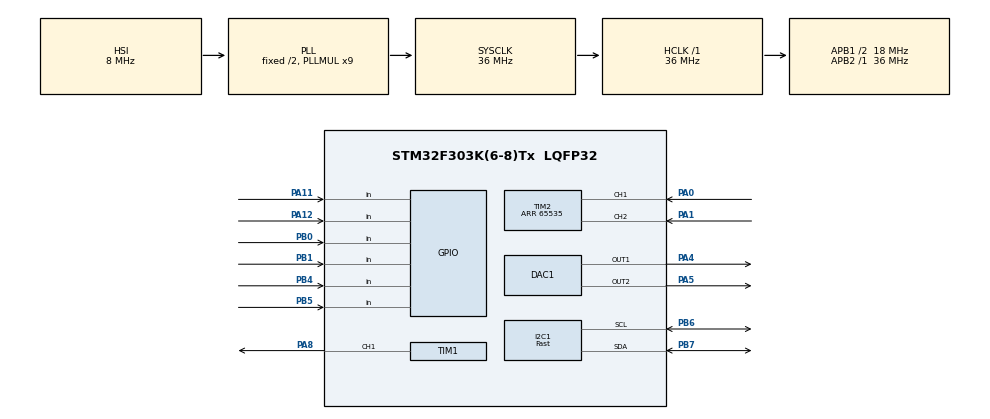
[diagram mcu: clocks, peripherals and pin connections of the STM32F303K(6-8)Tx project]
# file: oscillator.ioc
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DAC1.DAC_Trigger=DAC_TRIGGER_T6_TRGO
DAC1.DAC_Trigger2=DAC_TRIGGER_T6_TRGO
Dma.DAC1_CH1.0.Direction=DMA_MEMORY_TO_PERIPH
Dma.DAC1_CH1.0.Instance=DMA1_Channel3
Dma.DAC1_CH1.0.MemDataAlignment=DMA_MDATAALIGN_HALFWORD
Dma.DAC1_CH1.0.MemInc=DMA_MINC_ENABLE
Dma.DAC1_CH1.0.Mode=DMA_CIRCULAR
Dma.DAC1_CH1.0.PeriphDataAlignment=DMA_PDATAALIGN_HALFWORD
Dma.DAC1_CH1.0.PeriphInc=DMA_PINC_DISABLE
Dma.DAC1_CH1.0.Priority=DMA_PRIORITY_MEDIUM
Dma.Request0=DAC1_CH1
I2C1.I2C_Speed_Mode=I2C_Fast
I2C1.Timing=0x00301739
Mcu.Family=STM32F3
Mcu.Name=STM32F303K(6-8)Tx
Mcu.Package=LQFP32
NVIC.DMA1_Channel3_IRQn=true\:0\:0\:false\:false\:true\:false\:true\:true
NVIC.PriorityGroup=NVIC_PRIORITYGROUP_4
PA0.Signal=S_TIM2_CH1_ETR
PA1.Signal=S_TIM2_CH2
PA11.GPIO_PuPd=GPIO_PULLDOWN
PA11.Signal=GPIO_Input
PA12.GPIO_PuPd=GPIO_PULLDOWN
PA12.Signal=GPIO_Input
PA4.Signal=COMP_DAC11_group
PA5.Signal=COMP_DAC12_group
PA8.GPIO_Speed=GPIO_SPEED_FREQ_HIGH
PA8.Signal=S_TIM1_CH1
PB0.GPIO_PuPd=GPIO_PULLDOWN
PB0.Signal=GPIO_Input
PB1.GPIO_PuPd=GPIO_PULLDOWN
PB1.Signal=GPIO_Input
PB4.GPIO_PuPd=GPIO_PULLDOWN
PB4.Signal=GPIO_Input
PB5.GPIO_PuPd=GPIO_PULLDOWN
PB5.Signal=GPIO_Input
PB6.Mode=I2C
PB6.Signal=I2C1_SCL
PB7.Mode=I2C
PB7.Signal=I2C1_SDA
PF0\ /\ OSC_IN.Mode=HSE-External-Oscillator
PF0\ /\ OSC_IN.Signal=RCC_OSC_IN
PF1\ /\ OSC_OUT.Mode=HSE-External-Oscillator
PF1\ /\ OSC_OUT.Signal=RCC_OSC_OUT
ProjectManager.HeapSize=0x200
ProjectManager.StackSize=0x400
ProjectManager.TargetToolchain=STM32CubeIDE
RCC.AHBFreq_Value=36000000
RCC.APB1CLKDivider=RCC_HCLK_DIV2
RCC.APB1Freq_Value=18000000
RCC.APB1TimFreq_Value=36000000
RCC.APB2Freq_Value=36000000
RCC.APB2TimFreq_Value=36000000
RCC.CortexFreq_Value=36000000
RCC.HCLKFreq_Value=36000000
RCC.HSE_VALUE=8000000
RCC.HSI_VALUE=8000000
RCC.I2c1ClockSelection=RCC_I2C1CLKSOURCE_SYSCLK
RCC.PLLMUL=RCC_PLL_MUL9
RCC.SYSCLKFreq_VALUE=36000000
RCC.SYSCLKSourceVirtual=RCC_SYSCLKSOURCE_PLLCLK
SH.COMP_DAC11_group.0=DAC1_OUT1,DAC_OUT1
SH.COMP_DAC12_group.0=DAC1_OUT2,DAC_OUT2
SH.S_TIM1_CH1.0=TIM1_CH1,PWM Generation1 CH1
SH.S_TIM2_CH1_ETR.0=TIM2_CH1,Encoder_Interface
SH.S_TIM2_CH2.0=TIM2_CH2,Encoder_Interface
TIM1.AutoReloadPreload=TIM_AUTORELOAD_PRELOAD_ENABLE
TIM1.Channel-PWM\ Generation1\ CH1=TIM_CHANNEL_1
TIM2.EncoderMode=TIM_ENCODERMODE_TI12
TIM2.IC1Filter=5
TIM2.IC2Filter=5
TIM2.Period=65535
TIM6.TIM_MasterOutputTrigger=TIM_TRGO_UPDATE
VP_TIM1_VS_ClockSourceINT.Mode=Internal
VP_TIM6_VS_ClockSourceINT.Mode=Enable_Timer
board=custom

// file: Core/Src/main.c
/* USER CODE BEGIN Header */
/**
  ******************************************************************************
  * @file           : main.c
  * @brief          : Main program body
  ******************************************************************************
  * @attention
  *
  * Copyright (c) 2026 STMicroelectronics.
  * All rights reserved.
  *
  * This software is licensed under terms that can be found in the LICENSE file
  * in the root directory of this software component.
  * If no LICENSE file comes with this software, it is provided AS-IS.
  *
  ******************************************************************************
  */
/* USER CODE END Header */
#include "main.h"
#include "dac.h"
#include "dma.h"
#include "i2c.h"
#include "tim.h"
#include "gpio.h"

/* USER CODE BEGIN Includes */
#include "io.h"
#include "eventManager.h"
#include "display.h"
#include "signalGen.h"

/* USER CODE END Includes */

void SystemClock_Config(void);

/* USER CODE BEGIN 0 */

/**
 	f_TIM → reloj que entra al TIM1 (en tu caso 8 MHz)

	PSC → Prescaler
	ARR → valor máximo del contador (periodo)

	Qué hace realmente ARR
	El timer cuenta: 0 → 1 → 2 → ... → ARR → 0 → ...

	Cuando llega a ARR: Se reinicia a 0
	Se completa un periodo de PWM

	Por eso:

	ARR define cuántos ciclos de reloj del timer dura un periodo completo.
	Cuanto mayor es ARR → más tarda en completar el conteo → menor frecuencia.
	Cuanto menor es ARR → más rápido termina → mayor frecuencia.

	¿Cuándo usar PSC distinto de 0?

	Solo cuando:
	Necesitas frecuencias muy bajas
	ARR superaría 65535 (límite de 16 bits)
	Quieres un rango de ajuste más cómodo

 * **/
/* USER CODE END 0 */

int main(void){

  /* MCU Configuration--------------------------------------------------------*/

  /* Reset of all peripherals, Initializes the Flash interface and the Systick. */
  HAL_Init();

  /* Configure the system clock */
  SystemClock_Config();

  /* Initialize all configured peripherals */
  MX_GPIO_Init();
  MX_DMA_Init();
  MX_TIM1_Init();
  MX_DAC1_Init();
  MX_TIM6_Init();
  MX_TIM2_Init();
  MX_I2C1_Init();

  /* USER CODE BEGIN 2 */

  initOLED();
  enableEncoder(1);
  menuInit();

  /* Infinite loop */
  /* USER CODE BEGIN WHILE */

  while(1){

	kbdDriver();
	eventManager();
    /* USER CODE END WHILE */
  }
}

void SystemClock_Config(void)
{
  RCC_OscInitTypeDef RCC_OscInitStruct = {0};
  RCC_ClkInitTypeDef RCC_ClkInitStruct = {0};
  RCC_PeriphCLKInitTypeDef PeriphClkInit = {0};

  /** Initializes the RCC Oscillators according to the specified parameters
  * in the RCC_OscInitTypeDef structure.
  */
  RCC_OscInitStruct.OscillatorType = RCC_OSCILLATORTYPE_HSI;
  RCC_OscInitStruct.HSIState = RCC_HSI_ON;
  RCC_OscInitStruct.HSICalibrationValue = RCC_HSICALIBRATION_DEFAULT;
  RCC_OscInitStruct.PLL.PLLState = RCC_PLL_ON;
  RCC_OscInitStruct.PLL.PLLSource = RCC_PLLSOURCE_HSI;
  RCC_OscInitStruct.PLL.PLLMUL = RCC_PLL_MUL9;
  if (HAL_RCC_OscConfig(&RCC_OscInitStruct) != HAL_OK)
  {
    Error_Handler();
  }

  /** Initializes the CPU, AHB and APB buses clocks
  */
  RCC_ClkInitStruct.ClockType = RCC_CLOCKTYPE_HCLK|RCC_CLOCKTYPE_SYSCLK
                              |RCC_CLOCKTYPE_PCLK1|RCC_CLOCKTYPE_PCLK2;
  RCC_ClkInitStruct.SYSCLKSource = RCC_SYSCLKSOURCE_PLLCLK;
  RCC_ClkInitStruct.AHBCLKDivider = RCC_SYSCLK_DIV1;
  RCC_ClkInitStruct.APB1CLKDivider = RCC_HCLK_DIV2;
  RCC_ClkInitStruct.APB2CLKDivider = RCC_HCLK_DIV1;

  if (HAL_RCC_ClockConfig(&RCC_ClkInitStruct, FLASH_LATENCY_1) != HAL_OK)
  {
    Error_Handler();
  }
  PeriphClkInit.PeriphClockSelection = RCC_PERIPHCLK_I2C1|RCC_PERIPHCLK_TIM1;
  PeriphClkInit.I2c1ClockSelection = RCC_I2C1CLKSOURCE_SYSCLK;
  PeriphClkInit.Tim1ClockSelection = RCC_TIM1CLK_HCLK;
  if (HAL_RCCEx_PeriphCLKConfig(&PeriphClkInit) != HAL_OK)
  {
    Error_Handler();
  }
}

void Error_Handler(void)
{
  __disable_irq();
  while (1)
  {
  }
}
